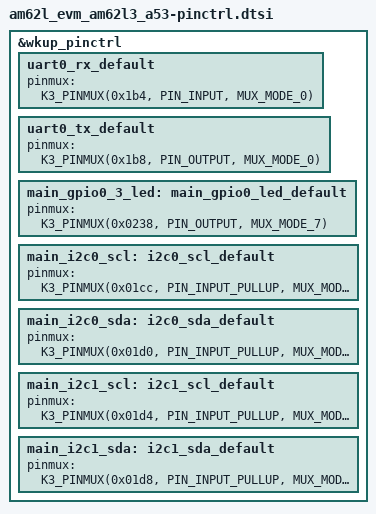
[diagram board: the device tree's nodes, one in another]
/*
 * Copyright (C) 2025 Texas Instruments Incorporated - https://www.ti.com/
 *
 * SPDX-License-Identifier: Apache-2.0
 */

&wkup_pinctrl {
	status = "okay";

	uart0_rx_default: uart0_rx_default {
		pinmux = <K3_PINMUX(0x1b4, PIN_INPUT, MUX_MODE_0)>; /* (D13) UART0_RXD */
	};

	uart0_tx_default: uart0_tx_default {
		pinmux = <K3_PINMUX(0x1b8, PIN_OUTPUT, MUX_MODE_0)>; /* (C13) UART0_TXD */
	};

	main_gpio0_3_led: main_gpio0_led_default {
		pinmux = <K3_PINMUX(0x0238, PIN_OUTPUT, MUX_MODE_7)>; /* (D6) MMC1_SDWP */
	};

	main_i2c0_scl: i2c0_scl_default {
		pinmux = <K3_PINMUX(0x01cc, PIN_INPUT_PULLUP, MUX_MODE_0)>; /* (B7) I2C0_SCL */
	};

	main_i2c0_sda: i2c0_sda_default {
		pinmux = <K3_PINMUX(0x01d0, PIN_INPUT_PULLUP, MUX_MODE_0)>; /* (A7) I2C0_SDA */
	};

	main_i2c1_scl: i2c1_scl_default {
		pinmux = <K3_PINMUX(0x01d4, PIN_INPUT_PULLUP, MUX_MODE_0)>; /* (D7) I2C1_SCL */
	};

	main_i2c1_sda: i2c1_sda_default {
		pinmux = <K3_PINMUX(0x01d8, PIN_INPUT_PULLUP, MUX_MODE_0)>; /* (A6) I2C1_SDA */
	};
};
